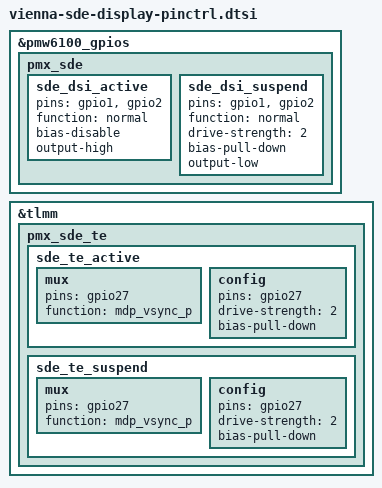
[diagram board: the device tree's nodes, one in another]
// SPDX-License-Identifier: BSD-3-Clause
/*
 * Copyright (c) 2025 Qualcomm Innovation Center, Inc. All rights reserved.
 */
&pmw6100_gpios {
	pmx_sde: pmx_sde {
		sde_dsi_active: sde_dsi_active {
				pins = "gpio1", "gpio2";
				function = "normal";
				bias-disable;
				output-high;
			};

		sde_dsi_suspend: sde_dsi_suspend {
				pins = "gpio1", "gpio2";
				function = "normal";
				drive-strength = <2>;
				bias-pull-down;	/* 2 mA */
				output-low;
		};
	};
};

&tlmm {
	pmx_sde_te: pmx_sde_te {
		sde_te_active: sde_te_active {
			mux {
				pins = "gpio27";
				function = "mdp_vsync_p";
			};

			config {
				pins = "gpio27";
				drive-strength = <2>;   /* 2 mA */
				bias-pull-down;         /* PULL DOWN */
			};
		};

		sde_te_suspend: sde_te_suspend {
			mux {
				pins = "gpio27";
				function = "mdp_vsync_p";
			};

			config {
				pins = "gpio27";
				drive-strength = <2>;	/* 2 mA */
				bias-pull-down;		/* PULL DOWN */
			};
		};
	};
};

